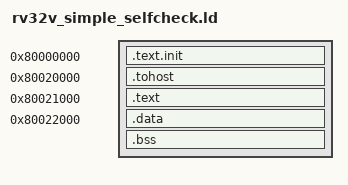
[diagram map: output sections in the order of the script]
/*
 * This linker script was automatically generated by the MicroTESK tool
 * Generation started: Fri Oct 11 19:18:20 AST 2019
 *
 * Institute for System Programming of the Russian Academy of Sciences (ISP RAS)
 * 25 Alexander Solzhenitsyn st., Moscow, 109004, Russia
 * http://forge.ispras.ru/projects/microtesk
 */

ENTRY(_start)
SECTIONS
{
  . = 0x80000000;
  .text.init : { *(".text.init")}
  . = 0x80020000;
  .tohost : { *(".tohost")}
  . = 0x80021000;
  .text : { *(".text")}
  . = 0x80022000;
  .data : { *(".data")}
  .bss : { *(".bss COMMON")}
  . = ALIGN(8);
  . = . + 0x10000;
  stack_top = .;
}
